# A34L71x register map
Vendor: ABOV Semiconductor Co., Ltd.; File version: 1.0
CPU: CM4 r0p1, little endian, MPU, FPU, VTOR, 4 interrupt priority bits
Registers are 32-bit, read-write, reset 0x0 unless marked. A register's access mark holds for its fields unless they carry their own. Offsets are from the block's base; [hi:lo] are bit positions; {n}, {i} and the like mark numbered series; 'fields as' and 'values as' point back to an identical list.

## LCD — LCD Driver
Base 0x40005000
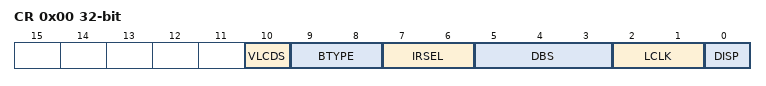
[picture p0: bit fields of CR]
0x00 CR — LCD Driver Control Register
  [10] VLCDS — Selection VLCD Power(only when a resistor bias type is selected)
    0=IntPower (Internal Power for VLCD); 1=ExtPower (External Power for VLCD)
  [9:8] BTYPE — LCD Bias Type Selection
    0=IntRBias (Internal Resistor Bias); 1=ExtRBias (External Resistor Bias); 2=CapBias (Capacitor Bias (Voltage Booster))
  [7:6] IRSEL — Internal LCD Bias Dividing Resistor Selection
    0=RLCD2 (100[kohm]); 1=RLCD1 (10[kohm]); 2=RLCD3 (50[kohm])
  [5:3] DBS — LCD Duty and Bias Selection
    0=8D4B (1/8 duty, 1/4 bias); 1=6D4B (1/6 duty, 1/4 bias); 2=5D3B (1/5 duty, 1/3 bias); 3=4D3B (1/4 duty, 1/3 bias); 4=3D3B (1/3 duty, 1/3 bias); 5=3D2B (1/3 duty, 1/2 bias); 6=2D2B (1/2 duty, 1/2 bias)
  [2:1] LCLK — LCD Clock Selection (When fLCD = 32.768kHz)
    0=128Hz (32.768kHz(fLCD) / 256); 1=256Hz (32.768kHz(fLCD) / 128); 2=512Hz (32.768kHz(fLCD) / 64); 3=1024Hz (32.768kHz(fLCD) / 32)
  [0] DISP — LCD Display Control
    0=Off (Display off); 1=On (Normal display on)
0x04 CCR — LCD Contrast Control Register
  [2:0] VLCD — VLC3 Voltage Control when the capacitor bias is selected by the BTYPE[1:0]
{0x10+i} DR{i} 8-bit (i=0..43) — LCD Display Data Register {i}

## VREFBUF — Voltage Reference buffer
Base 0x4000B000
0x00 SR — VREFBUF mode status register
  [0] VREF_ACT — VREF is stable
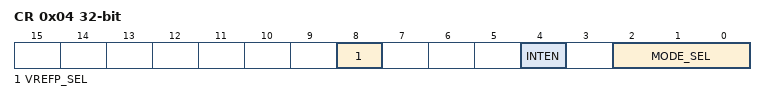
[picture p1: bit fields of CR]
0x04 CR — VREFBUF Control Register
  [8] VREFP_SEL — Select internal ref voltage when VREF_MODE=001
  [4] INTEN — Interrupt enable
  [2:0] MODE_SEL — VREF mode select
0x08 TCR reset 0x1FFFF — OPAMP1 Control Register
  [16:0] VREF_STIME — Set the VREF stabilization time (requires a stabilization time of 2 ms).

## OPAMP — Operational Amplifier
Base 0x4000B300
0x00 OPAMP_MR — OPAMP mode control register
  [0] LP_MODE_EN — Low power mode enable
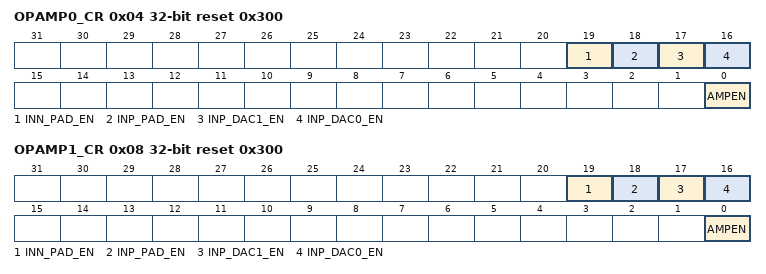
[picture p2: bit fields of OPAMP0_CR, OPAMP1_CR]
0x04 OPAMP0_CR reset 0x300 — OPAMP0 Control Register
  [19] INN_PAD_EN — OPAMP INN is connected to PAD
  [18] INP_PAD_EN — OPAMP INP is connected to PAD
  [17] INP_DAC1_EN — OPAMP INP is connected to DAC1
  [16] INP_DAC0_EN — OPAMP INP is connected to DAC0
  [0] AMPEN — Whether to enable or disable the OPAMP
0x08 OPAMP1_CR reset 0x300 — OPAMP1 Control Register
  fields as OPAMP0_CR

## DAC — 12-BIT Digital-to-analog (D/A) converter
Base 0x5000B800
Same registers: DAC0 0x4000B800, DAC1 0x4000B900
0x00 MR — 12bit DAC input data register
  [11:0] DIN — 12bit DAC input data
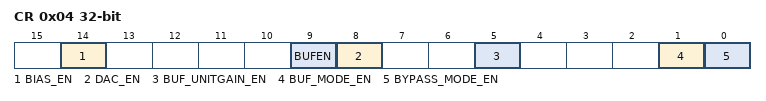
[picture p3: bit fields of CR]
0x04 CR — 12bit DAC Control Register
  [14] BIAS_EN — DAC IBIAS REF enable
  [9] BUFEN — DAC Buffer Enable Bit
  [8] DAC_EN — DAC Enable Bit
  [5] BUF_UNITGAIN_EN — DAC buffer unit gain mode
  [1] BUF_MODE_EN — DAC is connected to buffer
  [0] BYPASS_MODE_EN — DAC buffer bypass mode (buffer must be turned off)

## CRC — Cyclic Redundancy Check calculation module
Base 0x41002000
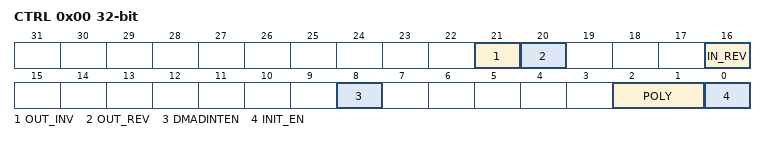
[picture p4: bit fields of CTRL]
0x00 CTRL — CRC control register
  [21] OUT_INV — Whether to enable or disable CRC output data inversion
  [20] OUT_REV — Reverse CRC output data
  [16] IN_REV — Reverse CRC input data
  [8] DMADINTEN — Whether to enable or disable the DMA done interrupt
  [2:1] POLY — Polynomial selection bit
    0=CRC32 (CRC32 (0x04C1_1DB7)); 1=CRC16_USB (CRC16_USB (0x8005)); 2=CRC16_CCITT (CRC16_CCITT (0x1021)); 3=CRC8_CCITT (CRC8_CCITT (0x07))
  [0] INIT_EN wo — Whether or not to apply the CRC initial value register (auto clear)
0x04 INIT reset 0xFFFFFFFF — CRC Init Data Register
  [31:0] INIT_EN — CRC Initial Value
0x08 IDR wo — CRC Input Data Register
  [31:0] IDR — CRC input data bits
0x08 ODR ro reset 0xFFFFFFFF — CRC Output Data Register
  [31:0] ODR — CRC output data bits
0x0C STAT — CRC Status Register
  [8] DMADINT — DMA Done Interrupt Flag Bit
